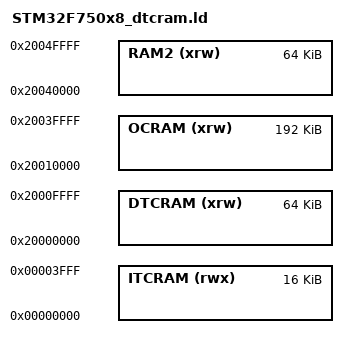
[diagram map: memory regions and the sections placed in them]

MEMORY
{
  ITCRAM (rwx) :  ORIGIN = 0x00000000, LENGTH = 16K
  DTCRAM (xrw) :  ORIGIN = 0x20000000, LENGTH = 64K

  OCRAM(xrw)   :  ORIGIN = 0x20010000, LENGTH = 192K
  RAM2(xrw)    :  ORIGIN = 0x20040000, LENGTH =  64K
}

REGION_ALIAS("TEXT", DTCRAM);
REGION_ALIAS("RAM", OCRAM);

INCLUDE armm_default_noflash.ld

